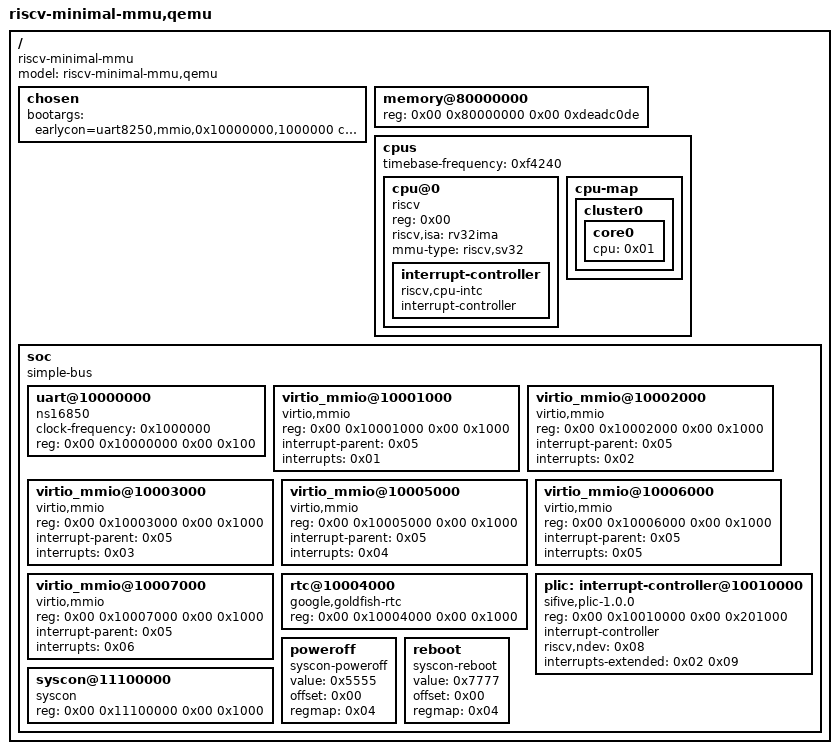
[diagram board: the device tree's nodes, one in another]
/dts-v1/;

/ {
	#address-cells = <0x02>;
	#size-cells = <0x02>;
	compatible = "riscv-minimal-mmu";
	model = "riscv-minimal-mmu,qemu";

	chosen {
		bootargs = "earlycon=uart8250,mmio,0x10000000,1000000 console=ttyS0 root=/dev/vda rw";
	};

	/* Memory size word (last word of reg) is patched at runtime with dtb_ptr */
	memory@80000000 {
		device_type = "memory";
		reg = <0x00 0x80000000 0x00 0xdeadc0de>;
	};

	cpus {
		#address-cells = <0x01>;
		#size-cells = <0x00>;
		timebase-frequency = <0xf4240>;

		cpu@0 {
			phandle = <0x01>;
			device_type = "cpu";
			reg = <0x00>;
			status = "okay";
			compatible = "riscv";
			riscv,isa = "rv32ima";
			mmu-type = "riscv,sv32";

			interrupt-controller {
				#interrupt-cells = <0x01>;
				interrupt-controller;
				compatible = "riscv,cpu-intc";
				phandle = <0x02>;
			};
		};

		cpu-map {
			cluster0 {
				core0 {
					cpu = <0x01>;
				};
			};
		};
	};

	soc {
		#address-cells = <0x02>;
		#size-cells = <0x02>;
		compatible = "simple-bus";
		ranges;

		uart@10000000 {
			clock-frequency = <0x1000000>;
			reg = <0x00 0x10000000 0x00 0x100>;
			compatible = "ns16850";
		};

		/* virtio-blk block device, wired through the PLIC (source 1) */
		virtio_mmio@10001000 {
			compatible = "virtio,mmio";
			reg = <0x00 0x10001000 0x00 0x1000>;
			interrupt-parent = <0x05>;
			interrupts = <0x01>;
		};

		/* virtio-net: NAT networking via the 3DS's WiFi (see virtio_net.h) */
		virtio_mmio@10002000 {
			compatible = "virtio,mmio";
			reg = <0x00 0x10002000 0x00 0x1000>;
			interrupt-parent = <0x05>;
			interrupts = <0x02>;
		};

		/* virtio-rng: real hardware entropy from the 3DS's PS service */
		virtio_mmio@10003000 {
			compatible = "virtio,mmio";
			reg = <0x00 0x10003000 0x00 0x1000>;
			interrupt-parent = <0x05>;
			interrupts = <0x03>;
		};

		/* virtio-blk #2: swap device (/dev/vdb), backed by a
		   sdmc:/swap.img the app creates at launch and removes on exit.
		   Guest RAM here is whatever the 3DS heap can spare (8-64MB),
		   so without swap anything substantial gets OOM-killed. Absent
		   at runtime if the file couldn't be created — the MMIO window
		   then reads back as zeroes, which fails the driver's magic-value
		   probe, so the guest just sees no device. */
		virtio_mmio@10005000 {
			compatible = "virtio,mmio";
			reg = <0x00 0x10005000 0x00 0x1000>;
			interrupt-parent = <0x05>;
			interrupts = <0x04>;
		};

		/* virtio-9p: 3DS filesystem passthrough (see virtio_9p.h). One
		   device exporting several trees, chosen per-mount with
		   `-o aname=`: sd (the real SD card), nand/twl (the NAND
		   filesystems, read-only, and only present with extended
		   homebrew permissions), and hw (synthetic sensor, camera,
		   mic and audio files). Mount tag is "3ds". */
		virtio_mmio@10006000 {
			compatible = "virtio,mmio";
			reg = <0x00 0x10006000 0x00 0x1000>;
			interrupt-parent = <0x05>;
			interrupts = <0x05>;
		};

		/* virtio-input: the accelerometer, gyroscope and the 3D/volume
		   sliders as a normal evdev node (see virtio_input.h). The same
		   readings are also in the hw 9P tree as text; this node is for
		   guest software that speaks evdev. */
		virtio_mmio@10007000 {
			compatible = "virtio,mmio";
			reg = <0x00 0x10007000 0x00 0x1000>;
			interrupt-parent = <0x05>;
			interrupts = <0x06>;
		};

		/* goldfish-rtc: real wall-clock time from the 3DS's hardware RTC.
		   Polled only (main.c latches the time on each register read),
		   no interrupt line needed. */
		rtc@10004000 {
			compatible = "google,goldfish-rtc";
			reg = <0x00 0x10004000 0x00 0x1000>;
		};

		/* PLIC: multiplexes virtio-blk/net/rng onto the CPU's single
		   S-mode external-interrupt line (SEIP). Without this, multiple
		   devices sharing that raw CPU interrupt directly (as they used
		   to) confuses the kernel's trap-entry nesting accounting and
		   crashes early in boot — see source/plic.h for the full story.
		   irq 9 = SEI (supervisor external interrupt), since the guest
		   kernel now boots directly in S-mode with no M-mode context. */
		plic: interrupt-controller@10010000 {
			compatible = "sifive,plic-1.0.0";
			reg = <0x00 0x10010000 0x00 0x201000>;
			interrupt-controller;
			#interrupt-cells = <0x01>;
			riscv,ndev = <0x08>;
			interrupts-extended = <0x02 0x09>;
			phandle = <0x05>;
		};

		poweroff {
			value = <0x5555>;
			offset = <0x00>;
			regmap = <0x04>;
			compatible = "syscon-poweroff";
		};

		reboot {
			value = <0x7777>;
			offset = <0x00>;
			regmap = <0x04>;
			compatible = "syscon-reboot";
		};

		syscon@11100000 {
			phandle = <0x04>;
			reg = <0x00 0x11100000 0x00 0x1000>;
			compatible = "syscon";
		};

		/* No clint@ node: an S-mode/SBI kernel gets the current time via
		   the `time` CSR and schedules its next interrupt via an SBI
		   ecall, rather than touching CLINT MMIO registers directly the
		   way the old M-mode/NOMMU boot did - so there's nothing here for
		   a DT node to bind to. main.c's timer bookkeeping (timerl/h/
		   timermatchl/h) is unchanged internally; it's just no longer
		   guest-visible as an MMIO device. */
	};
};
